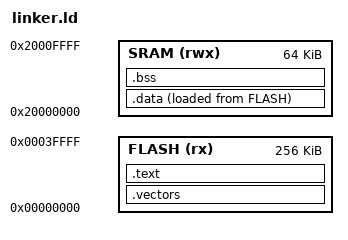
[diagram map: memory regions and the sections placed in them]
MEMORY
{
    FLASH (rx) : ORIGIN = 0x00000000, LENGTH = 256K
    SRAM (rwx) : ORIGIN = 0x20000000, LENGTH = 64K
}

SECTIONS
{
    .vectors :
    {
        *(.vectors)
    } > FLASH

    .text :
    {
        *(.text*)
        *(.rodata*)
    } > FLASH

    .data :
    {
        *(.data*)
    } > SRAM AT > FLASH

    .bss :
    {
        *(.bss*)
        *(COMMON)
    } > SRAM
}
